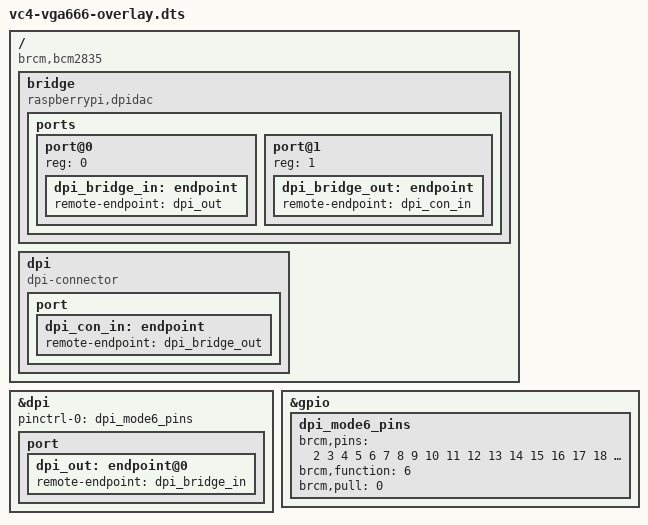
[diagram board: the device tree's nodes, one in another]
/dts-v1/;
/plugin/;

/ {
	compatible = "brcm,bcm2835", "brcm,bcm2708", "brcm,bcm2709", "brcm,bcm2712";

	fragment@0 {
		target-path = "/";
		__overlay__ {
			bridge: bridge {
				compatible = "raspberrypi,dpidac";
				#address-cells = <1>;
				#size-cells = <0>;

				ports {
					#address-cells = <1>;
					#size-cells = <0>;

					port@0 {
						reg = <0>;

						dpi_bridge_in: endpoint {
							remote-endpoint = <&dpi_out>;
						};
					};

					port@1 {
						reg = <1>;

						dpi_bridge_out: endpoint {
							remote-endpoint = <&dpi_con_in>;
						};
					};
				};
			};

			dpi {
				compatible = "dpi-connector";

				port {
					dpi_con_in: endpoint {
						remote-endpoint = <&dpi_bridge_out>;
					};
				};
			};
		};
	};

	fragment@1 {
		target = <&dpi>;
		__overlay__  {
			status = "okay";
			pinctrl-names = "default";
			pinctrl-0 = <&dpi_mode6_pins>;
			port {
				dpi_out: endpoint@0 {
					remote-endpoint = <&dpi_bridge_in>;
				};
			};
		};
	};

	fragment@2 {
		target = <&gpio>;
		__overlay__ {
			dpi_mode6_pins: dpi_mode6_pins {
				brcm,pins = <2 3 4 5 6 7 8 9 10 11 12 13 14 15 16 17 18 19 20 21>;
				brcm,function = <6>;
				brcm,pull = <0>;
			};
		};
	};
};
